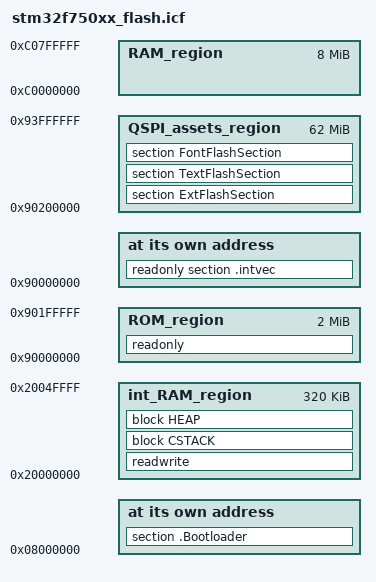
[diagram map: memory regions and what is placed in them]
/*###ICF### Section handled by ICF editor, don't touch! ****/
/*-Editor annotation file-*/
/* IcfEditorFile="$TOOLKIT_DIR$\config\ide\IcfEditor\cortex_v1_0.xml" */
/*-Specials-*/
define symbol __ICFEDIT_intvec_start__ =  0x90000000;
export symbol __ICFEDIT_intvec_start__;
/*-Memory Regions-*/
define symbol __ICFEDIT_region_ROM_start__      = 0x90000000;
define symbol __ICFEDIT_region_ROM_end__        = 0x901FFFFF;
define symbol __ICFEDIT_region_RAM_start__      = 0xC0000000;
define symbol __ICFEDIT_region_RAM_end__        = 0xC07FFFFF;
define symbol __ICFEDIT_region_int_RAM_start__  = 0x20000000;
define symbol __ICFEDIT_region_int_RAM_end__    = 0x2004FFFF;

define symbol __ICFEDIT_region_QSPI_assets_start__  = 0x90200000;
define symbol __ICFEDIT_region_QSPI_assets_end__    = 0x93FFFFFF;

/*-Sizes-*/
define symbol __ICFEDIT_size_cstack__ = 0x400;
define symbol __ICFEDIT_size_heap__ = 0x200;
/**** End of ICF editor section. ###ICF###*/

define memory mem with size = 4G;
define region ROM_region         = mem:[from __ICFEDIT_region_ROM_start__         to __ICFEDIT_region_ROM_end__];
define region QSPI_assets_region = mem:[from __ICFEDIT_region_QSPI_assets_start__ to __ICFEDIT_region_QSPI_assets_end__];
define region RAM_region         = mem:[from __ICFEDIT_region_RAM_start__         to __ICFEDIT_region_RAM_end__];
define region int_RAM_region     = mem:[from __ICFEDIT_region_int_RAM_start__     to __ICFEDIT_region_int_RAM_end__];

define block CSTACK    with alignment = 8, size = __ICFEDIT_size_cstack__   { };
define block HEAP      with alignment = 8, size = __ICFEDIT_size_heap__     { };

initialize by copy { readwrite };
do not initialize  { section .noinit };

place at address mem:__ICFEDIT_intvec_start__ { readonly section .intvec };
place at address mem:0x08000000 { section .Bootloader };
place in ROM_region     { readonly };
place in int_RAM_region { readwrite, block CSTACK, block HEAP };

place in QSPI_assets_region { section ExtFlashSection, section TextFlashSection, section FontFlashSection };

